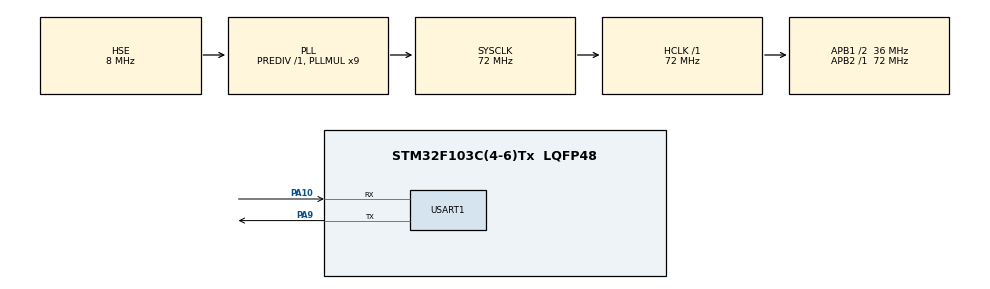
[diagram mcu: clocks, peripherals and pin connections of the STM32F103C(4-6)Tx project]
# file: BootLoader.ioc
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Mcu.Family=STM32F1
Mcu.Name=STM32F103C(4-6)Tx
Mcu.Package=LQFP48
NVIC.PriorityGroup=NVIC_PRIORITYGROUP_4
PA10.Mode=Asynchronous
PA10.Signal=USART1_RX
PA13.Mode=Serial_Wire
PA13.Signal=SYS_JTMS-SWDIO
PA14.Mode=Serial_Wire
PA14.Signal=SYS_JTCK-SWCLK
PA9.Mode=Asynchronous
PA9.Signal=USART1_TX
PC14-OSC32_IN.Mode=LSE-External-Oscillator
PC14-OSC32_IN.Signal=RCC_OSC32_IN
PC15-OSC32_OUT.Mode=LSE-External-Oscillator
PC15-OSC32_OUT.Signal=RCC_OSC32_OUT
PD0-OSC_IN.Mode=HSE-External-Oscillator
PD0-OSC_IN.Signal=RCC_OSC_IN
PD1-OSC_OUT.Mode=HSE-External-Oscillator
PD1-OSC_OUT.Signal=RCC_OSC_OUT
ProjectManager.HeapSize=0x200
ProjectManager.StackSize=0x400
ProjectManager.TargetToolchain=MDK-ARM V5
RCC.AHBFreq_Value=72000000
RCC.APB1CLKDivider=RCC_HCLK_DIV2
RCC.APB1Freq_Value=36000000
RCC.APB1TimFreq_Value=72000000
RCC.APB2Freq_Value=72000000
RCC.APB2TimFreq_Value=72000000
RCC.HCLKFreq_Value=72000000
RCC.PLLMUL=RCC_PLL_MUL9
RCC.PLLSourceVirtual=RCC_PLLSOURCE_HSE
RCC.SYSCLKFreq_VALUE=72000000
RCC.SYSCLKSource=RCC_SYSCLKSOURCE_PLLCLK
RCC.USBFreq_Value=72000000
USART1.VirtualMode=VM_ASYNC
board=custom

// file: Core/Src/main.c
/* USER CODE BEGIN Header */
/**
  ******************************************************************************
  * @file           : main.c
  * @brief          : Main program body
  ******************************************************************************
  * @attention
  *
  * Copyright (c) 2025 STMicroelectronics.
  * All rights reserved.
  *
  * This software is licensed under terms that can be found in the LICENSE file
  * in the root directory of this software component.
  * If no LICENSE file comes with this software, it is provided AS-IS.
  *
  ******************************************************************************
  */
/* USER CODE END Header */
#include "main.h"
#include "usart.h"
#include "gpio.h"
#include "stdio.h"

void SystemClock_Config(void);

/* USER CODE BEGIN 0 */

/*********************************************************************
项目使用的单片机是 STM32F103C6T6 他的Flash是32K 也就是 0x800_0000 - 0x800_8000
我使用 0x0x800_0000 - 0x800_3000 存放 Bootloader
  使用 0x0x800_3000 - 0x800_8000 存放 App 代码

**********************************************************************/

// 函数指针重定义
typedef  void (*pFunction)(void);
// APP代码的存储地址
#define ApplicationAddress 0x8003000

pFunction Jump_To_Application;
uint32_t  JumpAddress;

int JumpToApplication()
{
	// 1、判断 APP 首地址中存储的数据是不是 0x2000 开头的，因为内存地址在这里
    // 在STM32中，SRAM通常从0x20000000开始，大小因芯片而异（如20KB、64KB、128KB等）。
    // 这个掩码0x2FFE0000是为了屏蔽掉低位地址变化，只保留SRAM区域的高位特征。
	if( ( ( *(__IO uint32_t*)ApplicationAddress ) & 0x2FFE0000 ) == 0x20000000 )
	{
		printf("\r\n Run to app.\r\n");
		// 2、获取APP的 复位程序 的地址，也就是APP的入口函数地址，
		JumpAddress = *(__IO uint32_t*) (ApplicationAddress + 4);
		// 3、把该地址转化成实际的函数
		Jump_To_Application = (pFunction) JumpAddress;
		// 4、把APP的初始栈顶地址加载到MSP寄存器中。
		__set_MSP(*(__IO uint32_t*) ApplicationAddress);
		// 5、跳转到APP的Reset_Handler，也就是APP的启动代码，之后APP会初始化自己的系统、调用main()。
		Jump_To_Application();
		return 0;
	}
	else
	{
		printf("\r\n Run to app error.\r\n");
		return -1;
	}
}

/* USER CODE END 0 */

int main(void)
{

  /* MCU Configuration--------------------------------------------------------*/

  /* Reset of all peripherals, Initializes the Flash interface and the Systick. */
  HAL_Init();

  /* Configure the system clock */
  SystemClock_Config();

  /* Initialize all configured peripherals */
  MX_GPIO_Init();
  MX_USART1_UART_Init();
  /* USER CODE BEGIN 2 */
	printf("**************************************\r\n");
	printf("          BootLoaderBasic             \r\n");
	printf("                V1                    \r\n");
	printf("**************************************\r\n");

	JumpToApplication();

  /* USER CODE END 2 */

  /* Infinite loop */
  while (1)
  {

  }
}

void SystemClock_Config(void)
{
  RCC_OscInitTypeDef RCC_OscInitStruct = {0};
  RCC_ClkInitTypeDef RCC_ClkInitStruct = {0};

  /** Initializes the RCC Oscillators according to the specified parameters
  * in the RCC_OscInitTypeDef structure.
  */
  RCC_OscInitStruct.OscillatorType = RCC_OSCILLATORTYPE_HSE;
  RCC_OscInitStruct.HSEState = RCC_HSE_ON;
  RCC_OscInitStruct.HSEPredivValue = RCC_HSE_PREDIV_DIV1;
  RCC_OscInitStruct.HSIState = RCC_HSI_ON;
  RCC_OscInitStruct.PLL.PLLState = RCC_PLL_ON;
  RCC_OscInitStruct.PLL.PLLSource = RCC_PLLSOURCE_HSE;
  RCC_OscInitStruct.PLL.PLLMUL = RCC_PLL_MUL9;
  if (HAL_RCC_OscConfig(&RCC_OscInitStruct) != HAL_OK)
  {
    Error_Handler();
  }

  /** Initializes the CPU, AHB and APB buses clocks
  */
  RCC_ClkInitStruct.ClockType = RCC_CLOCKTYPE_HCLK|RCC_CLOCKTYPE_SYSCLK
                              |RCC_CLOCKTYPE_PCLK1|RCC_CLOCKTYPE_PCLK2;
  RCC_ClkInitStruct.SYSCLKSource = RCC_SYSCLKSOURCE_PLLCLK;
  RCC_ClkInitStruct.AHBCLKDivider = RCC_SYSCLK_DIV1;
  RCC_ClkInitStruct.APB1CLKDivider = RCC_HCLK_DIV2;
  RCC_ClkInitStruct.APB2CLKDivider = RCC_HCLK_DIV1;

  if (HAL_RCC_ClockConfig(&RCC_ClkInitStruct, FLASH_LATENCY_2) != HAL_OK)
  {
    Error_Handler();
  }
}

void Error_Handler(void)
{
  __disable_irq();
  while (1)
  {
  }
}
